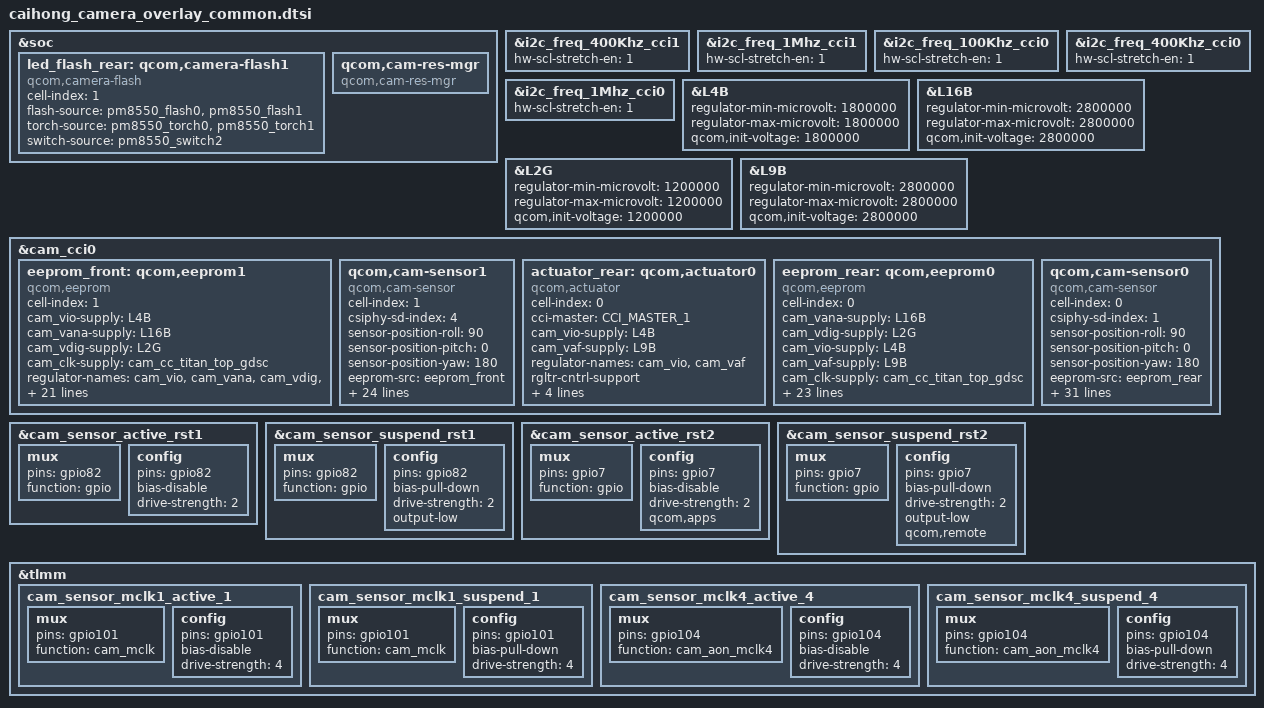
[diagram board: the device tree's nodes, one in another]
#include <dt-bindings/msm-camera.h>

&soc {
	led_flash_rear: qcom,camera-flash1 {
		cell-index = <1>;
		compatible = "qcom,camera-flash";
		flash-source = <&pm8550_flash0 &pm8550_flash1>;
		torch-source = <&pm8550_torch0 &pm8550_torch1>;
		switch-source = <&pm8550_switch2>;
		status = "ok";
	};

	qcom,cam-res-mgr {
		compatible = "qcom,cam-res-mgr";
		status = "ok";
	};
};

&i2c_freq_400Khz_cci1 {
    hw-scl-stretch-en = <1>;
};

&i2c_freq_1Mhz_cci1 {
    hw-scl-stretch-en = <1>;
};

&i2c_freq_100Khz_cci0 {
    hw-scl-stretch-en = <1>;
};

&i2c_freq_400Khz_cci0 {
    hw-scl-stretch-en = <1>;
};

&i2c_freq_1Mhz_cci0 {
    hw-scl-stretch-en = <1>;
};


//iovdd
&L4B {
  regulator-min-microvolt = <1800000>;
  regulator-max-microvolt = <1800000>;
  qcom,init-voltage = <1800000>;
};
//avdd
&L16B {
  regulator-min-microvolt = <2800000>;
  regulator-max-microvolt = <2800000>;
  qcom,init-voltage = <2800000>;
};
//cam0 dvdd
&L2G {
  regulator-min-microvolt = <1200000>;
  regulator-max-microvolt = <1200000>;
  qcom,init-voltage = <1200000>;
};
//cam1 dvdd
//&L11B {
//  regulator-min-microvolt = <1200000>;
//  regulator-max-microvolt = <1200000>;
//  qcom,init-voltage = <1200000>;
//};
//cam0 af
&L9B {
  regulator-min-microvolt = <2800000>;
  regulator-max-microvolt = <2800000>;
  qcom,init-voltage = <2800000>;
};

&cam_cci0 {
	eeprom_front: qcom,eeprom1 {
		cell-index = <1>;
		compatible = "qcom,eeprom";
		cam_vio-supply = <&L4B>;
		cam_vana-supply = <&L16B>;
		cam_vdig-supply = <&L2G>;
		cam_clk-supply = <&cam_cc_titan_top_gdsc>;
		regulator-names = "cam_vio", "cam_vana",
			"cam_vdig", "cam_clk";
		rgltr-cntrl-support;
		rgltr-min-voltage = <1800000 2800000 1200000 0>;
		rgltr-max-voltage = <1800000 2800000 1200000 0>;
		rgltr-load-current = <300000 600000 600000 0>;
		gpio-no-mux = <0>;
		pinctrl-names = "cam_default", "cam_suspend";
		pinctrl-0 = <&cam_sensor_mclk4_active_4
				 &cam_sensor_active_rst2>;
		pinctrl-1 = <&cam_sensor_mclk4_suspend_4
				 &cam_sensor_suspend_rst2>;
		gpios = <&tlmm 104 0>,
			<&tlmm 7 0>;
		gpio-reset = <1>;
		gpio-req-tbl-num = <0 1>;
		gpio-req-tbl-flags = <1 0>;
		gpio-req-tbl-label = "CAMIF_MCLK4",
					"CAM_RESET2";
		cci-master = <CCI_MASTER_0>;
		clocks = <&camcc CAM_CC_MCLK4_CLK>;
		clock-names = "cam_clk";
		clock-cntl-level = "nominal";
		clock-rates = <19200000>;
		insensor-page-eeprom-support = <1>;
		oplus-eeprom-name = "sc820cs_caihong";
		status = "ok";
	};

    //front camera
	qcom,cam-sensor1 {
		cell-index = <1>;
		compatible = "qcom,cam-sensor";
		csiphy-sd-index = <4>;
		sensor-position-roll = <90>;
		sensor-position-pitch = <0>;
		sensor-position-yaw = <180>;
		eeprom-src = <&eeprom_front>;
		cam_vio-supply = <&L4B>;
		cam_vana-supply = <&L16B>;
		cam_vdig-supply = <&L2G>;
		cam_clk-supply = <&cam_cc_titan_top_gdsc>;
		regulator-names = "cam_vio", "cam_vana",
			"cam_vdig", "cam_clk";
		rgltr-cntrl-support;
		rgltr-min-voltage = <1800000 2800000 1200000 0>;
		rgltr-max-voltage = <1800000 2800000 1200000 0>;
		rgltr-load-current = <300000 600000 600000 0>;
		gpio-no-mux = <0>;
		pinctrl-names = "cam_default", "cam_suspend";
		pinctrl-0 = <&cam_sensor_mclk4_active_4
				 &cam_sensor_active_rst2>;
		pinctrl-1 = <&cam_sensor_mclk4_suspend_4
				 &cam_sensor_suspend_rst2>;
		gpios = <&tlmm 104 0>,
			<&tlmm 7 0>;
		gpio-reset = <1>;
		gpio-req-tbl-num = <0 1>;
		gpio-req-tbl-flags = <1 0>;
		gpio-req-tbl-label = "CAMIF_MCLK4",
					"CAM_RESET2";
		cci-master = <CCI_MASTER_0>;
		clocks = <&camcc CAM_CC_MCLK4_CLK>;
		clock-names = "cam_clk";
		clock-cntl-level = "nominal";
		clock-rates = <19200000>;
		status = "ok";
	};

};

&cam_cci0 {
	actuator_rear: qcom,actuator0{
		cell-index = <0>;
		compatible = "qcom,actuator";
		cci-master = <CCI_MASTER_1>;
		cam_vio-supply = <&L4B>;
		cam_vaf-supply = <&L9B>;
		regulator-names = "cam_vio", "cam_vaf";
		rgltr-cntrl-support;
		rgltr-min-voltage = <1800000 2800000>;
		rgltr-max-voltage = <1800000 2800000>;
		rgltr-load-current = <300000 1200000>;
		//reactive-ctrl-support;
		//                       reg_addr   addr_type   reg_data    data_type   delay       data_mask
		//reactive-reg-setting = < 0x02       1           0x00        1           2800        0x00 >;
		actuator,name = "gt9772";
		status = "ok";
	};
	eeprom_rear: qcom,eeprom0 {
		cell-index = <0>;
		compatible = "qcom,eeprom";
		cam_vana-supply = <&L16B>;
		cam_vdig-supply = <&L2G>;
		cam_vio-supply = <&L4B>;
		cam_vaf-supply = <&L9B>;
		cam_clk-supply = <&cam_cc_titan_top_gdsc>;
		regulator-names = "cam_vana", "cam_vdig", "cam_vio", "cam_vaf",
		                  "cam_clk";
		rgltr-cntrl-support;
		rgltr-min-voltage = <2800000 1200000 1800000 2800000 0>;
		rgltr-max-voltage = <2800000 1200000 1800000 2800000 0>;
		rgltr-load-current = <600000 1200000 300000 1200000 0>;
		gpio-no-mux = <0>;
		pinctrl-names = "cam_default", "cam_suspend";
		pinctrl-0 = <&cam_sensor_mclk1_active_1
				&cam_sensor_active_rst1>;
		pinctrl-1 = <&cam_sensor_mclk1_suspend_1
				&cam_sensor_suspend_rst1>;
		gpios = <&tlmm 101 0>,
			<&tlmm 82 0>;
		gpio-reset = <1>;
		gpio-req-tbl-num = <0 1>;
		gpio-req-tbl-flags = <1 0>;
		gpio-req-tbl-label = "CAMIF_MCLK1",
					"CAM_RESET1";
		cci-master = <CCI_MASTER_1>;
		clocks = <&camcc CAM_CC_MCLK1_CLK>;
		clock-names = "cam_clk";
		clock-cntl-level = "nominal";
		clock-rates = <19200000>;
		status = "ok";
	};

    //main camera
	qcom,cam-sensor0 {
		cell-index = <0>;
		compatible = "qcom,cam-sensor";
		csiphy-sd-index = <1>;
		sensor-position-roll = <90>;
		sensor-position-pitch = <0>;
		sensor-position-yaw = <180>;
		eeprom-src = <&eeprom_rear>;
		actuator-src = <&actuator_rear>;
		led-flash-src = <&led_flash_rear>;
		cam_vana-supply = <&L16B>;
		cam_vdig-supply = <&L2G>;
		cam_vio-supply = <&L4B>;
		cam_vaf-supply = <&L9B>;
		cam_clk-supply = <&cam_cc_titan_top_gdsc>;
		regulator-names = "cam_vana", "cam_vdig", "cam_vio", "cam_vaf",
		                  "cam_clk";
		rgltr-cntrl-support;
		rgltr-min-voltage = <2800000 1200000 1800000 2800000 0>;
		rgltr-max-voltage = <2800000 1200000 1800000 2800000 0>;
		rgltr-load-current = <300000 1200000 600000 600000 0>;
		gpio-no-mux = <0>;
		pinctrl-names = "cam_default", "cam_suspend";
		pinctrl-0 = <&cam_sensor_mclk1_active_1
				&cam_sensor_active_rst1>;
		pinctrl-1 = <&cam_sensor_mclk1_suspend_1
				&cam_sensor_suspend_rst1>;
		gpios = <&tlmm 101 0>,
			<&tlmm 82 0>;
		gpio-reset = <1>;
		gpio-req-tbl-num = <0 1>;
		gpio-req-tbl-flags = <1 0>;
		gpio-req-tbl-label = "CAMIF_MCLK1",
					"CAM_RESET1";
		cci-master = <CCI_MASTER_1>;
		clocks = <&camcc CAM_CC_MCLK1_CLK>;
		clock-names = "cam_clk";
		clock-cntl-level = "nominal";
		clock-rates = <19200000>;
		//is-support-laser = <1>;
		//enable_qsc_write_in_advance = <1>;
		//qsc_reg_addr = <0x24C0>;
		eeprom_slave_addr = <0xA0>;
		//qsc_data_size = <2304>;
		//write_qsc_addr = <0x5800>;
		status = "ok";
	};
};


&cam_sensor_active_rst1 {
	mux {
		pins = "gpio82";
		function = "gpio";
	};

	config {
		pins = "gpio82";
		bias-disable; /* No PULL */
		drive-strength = <2>; /* 2 MA */
	};
};

&cam_sensor_suspend_rst1 {
	mux {
		pins = "gpio82";
		function = "gpio";
	};

	config {
		pins = "gpio82";
		bias-pull-down; /* PULL DOWN */
		drive-strength = <2>; /* 2 MA */
		output-low;
	};
};

&cam_sensor_active_rst2 {
	mux {
		pins = "gpio7";
		function = "gpio";
	};

	config {
		pins = "gpio7";
		bias-disable; /* No PULL */
		drive-strength = <2>; /* 2 MA */
		qcom,apps;
	};
};

&cam_sensor_suspend_rst2 {
	mux {
		pins = "gpio7";
		function = "gpio";
	};

	config {
		pins = "gpio7";
		bias-pull-down; /* PULL DOWN */
		drive-strength = <2>; /* 2 MA */
		output-low;
		qcom,remote;
	};
};
&tlmm {
    cam_sensor_mclk1_active_1: cam_sensor_mclk1_active_1 {
        /* MCLK1 */
        mux {
            pins = "gpio101";
            function = "cam_mclk";
        };

        config {
            pins = "gpio101";
            bias-disable; /* No PULL */
            drive-strength = <4>; /* 2 MA */
        };
    };

    cam_sensor_mclk1_suspend_1: cam_sensor_mclk1_suspend_1 {
        /* MCLK1 */
        mux {
            pins = "gpio101";
            function = "cam_mclk";
        };

        config {
            pins = "gpio101";
            bias-pull-down; /* PULL DOWN */
            drive-strength = <4>; /* 2 MA */
        };
    };

    cam_sensor_mclk4_active_4: cam_sensor_mclk4_active_4 {
        /* MCLK4 */
        mux {
            pins = "gpio104";
            function = "cam_aon_mclk4";
        };

        config {
            pins = "gpio104";
            bias-disable; /* No PULL */
            drive-strength = <4>; /* 2 MA */
        };
    };

    cam_sensor_mclk4_suspend_4: cam_sensor_mclk4_suspend_4 {
        /* MCLK4 */
        mux {
            pins = "gpio104";
            function = "cam_aon_mclk4";
    };

        config {
            pins = "gpio104";
            bias-pull-down; /* PULL DOWN */
            drive-strength = <4>; /* 2 MA */
        };
    };

};
